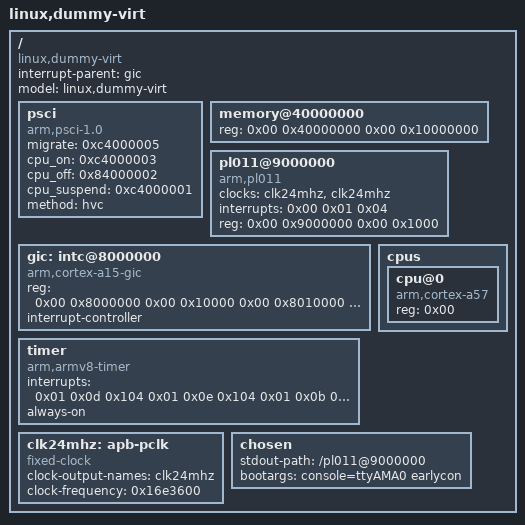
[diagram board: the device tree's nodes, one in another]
// SPDX-License-Identifier: GPL-2.0
/*
 * Minimal devicetree for QEMU's aarch64 "virt" machine: just enough to
 * bring up a single CPU and get a console on the PL011 UART. Captured
 * from QEMU's own auto-generated DTB and trimmed of everything not
 * needed for that (virtio-mmio, PCIe, flash, RTC, GPIO, fw-cfg, ...).
 *
 * Companion to arch/arm64/configs/virt_uart_defconfig. Matches:
 *   qemu-system-aarch64 -M virt -cpu cortex-a57 -smp 1 -m 256 -nographic \
 *       -kernel arch/arm64/boot/Image \
 *       -dtb arch/arm64/boot/dts/qemu/qemu-virt-uart-min.dtb
 *
 * memory/cpu/gic nodes are static, unlike QEMU's generated DTB which
 * adapts to -smp/-m/-cpu: this one only matches the invocation above.
 */

/dts-v1/;

/ {
	interrupt-parent = <&gic>;
	model = "linux,dummy-virt";
	#size-cells = <0x02>;
	#address-cells = <0x02>;
	compatible = "linux,dummy-virt";

	psci {
		migrate = <0xc4000005>;
		cpu_on = <0xc4000003>;
		cpu_off = <0x84000002>;
		cpu_suspend = <0xc4000001>;
		method = "hvc";
		compatible = "arm,psci-1.0\0arm,psci-0.2\0arm,psci";
	};

	memory@40000000 {
		reg = <0x00 0x40000000 0x00 0x10000000>;
		device_type = "memory";
	};

	pl011@9000000 {
		clock-names = "uartclk\0apb_pclk";
		clocks = <&clk24mhz &clk24mhz>;
		interrupts = <0x00 0x01 0x04>;
		reg = <0x00 0x9000000 0x00 0x1000>;
		compatible = "arm,pl011\0arm,primecell";
	};

	gic: intc@8000000 {
		reg = <0x00 0x8000000 0x00 0x10000 0x00 0x8010000 0x00 0x10000>;
		compatible = "arm,cortex-a15-gic";
		ranges;
		#size-cells = <0x02>;
		#address-cells = <0x02>;
		interrupt-controller;
		#interrupt-cells = <0x03>;
	};

	cpus {
		#size-cells = <0x00>;
		#address-cells = <0x01>;

		cpu@0 {
			reg = <0x00>;
			compatible = "arm,cortex-a57";
			device_type = "cpu";
		};
	};

	timer {
		interrupts = <0x01 0x0d 0x104 0x01 0x0e 0x104 0x01 0x0b 0x104 0x01 0x0a 0x104>;
		always-on;
		compatible = "arm,armv8-timer\0arm,armv7-timer";
	};

	clk24mhz: apb-pclk {
		clock-output-names = "clk24mhz";
		clock-frequency = <0x16e3600>;
		#clock-cells = <0x00>;
		compatible = "fixed-clock";
	};

	chosen {
		stdout-path = "/pl011@9000000";
		bootargs = "console=ttyAMA0 earlycon";
	};
};
